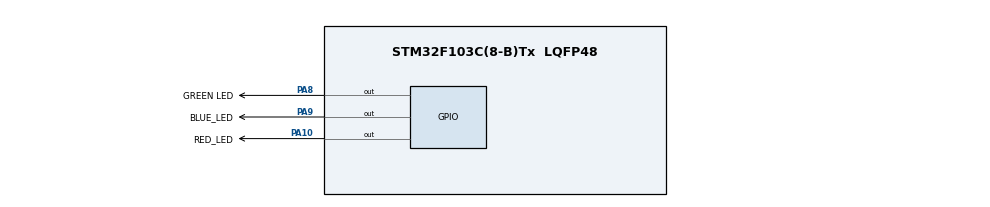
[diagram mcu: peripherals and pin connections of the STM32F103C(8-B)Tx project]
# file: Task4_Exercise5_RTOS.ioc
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FREERTOS.Tasks01=defaultTask,24,128,StartDefaultTask,Default,NULL,Dynamic,NULL,NULL;GreenLedTask,24,128,FlashGreenLedTask,Default,NULL,Dynamic,NULL,NULL;RedLedTask,32,128,FlashRedLedTask,Default,NULL,Dynamic,NULL,NULL
FREERTOS.configUSE_NEWLIB_REENTRANT=1
Mcu.Family=STM32F1
Mcu.Name=STM32F103C(8-B)Tx
Mcu.Package=LQFP48
NVIC.PriorityGroup=NVIC_PRIORITYGROUP_4
NVIC.TIM4_IRQn=true\:15\:0\:false\:false\:true\:false\:false\:true\:true
NVIC.TimeBase=TIM4_IRQn
NVIC.TimeBaseIP=TIM4
PA10.GPIO_Label=RED_LED
PA10.Signal=GPIO_Output
PA13.Mode=Serial_Wire
PA13.Signal=SYS_JTMS-SWDIO
PA14.Mode=Serial_Wire
PA14.Signal=SYS_JTCK-SWCLK
PA8.GPIO_Label=GREEN LED
PA8.Signal=GPIO_Output
PA9.GPIO_Label=BLUE_LED
PA9.Signal=GPIO_Output
ProjectManager.HeapSize=0x200
ProjectManager.StackSize=0x400
ProjectManager.TargetToolchain=STM32CubeIDE
RCC.APB1Freq_Value=8000000
RCC.APB2Freq_Value=8000000
VP_FREERTOS_VS_CMSIS_V2.Mode=CMSIS_V2
VP_SYS_VS_tim4.Mode=TIM4
board=custom

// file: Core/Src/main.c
/* USER CODE BEGIN Header */
/**
  ******************************************************************************
  * @file           : main.c
  * @brief          : Main program body
  ******************************************************************************
  * @attention
  *
  * Copyright (c) 2024 STMicroelectronics.
  * All rights reserved.
  *
  * This software is licensed under terms that can be found in the LICENSE file
  * in the root directory of this software component.
  * If no LICENSE file comes with this software, it is provided AS-IS.
  *
  ******************************************************************************
  */
/* USER CODE END Header */
#include "main.h"
#include "cmsis_os.h"

/* Definitions for defaultTask */
osThreadId_t defaultTaskHandle;
const osThreadAttr_t defaultTask_attributes = {
  .name = "defaultTask",
  .stack_size = 128 * 4,
  .priority = (osPriority_t) osPriorityNormal,
};
/* Definitions for GreenLedTask */
osThreadId_t GreenLedTaskHandle;
const osThreadAttr_t GreenLedTask_attributes = {
  .name = "GreenLedTask",
  .stack_size = 128 * 4,
  .priority = (osPriority_t) osPriorityNormal,
};
/* Definitions for RedLedTask */
osThreadId_t RedLedTaskHandle;
const osThreadAttr_t RedLedTask_attributes = {
  .name = "RedLedTask",
  .stack_size = 128 * 4,
  .priority = (osPriority_t) osPriorityAboveNormal,
};

void SystemClock_Config(void);
static void MX_GPIO_Init(void);
void StartDefaultTask(void *argument);
void FlashGreenLedTask(void *argument);
void FlashRedLedTask(void *argument);

/* USER CODE BEGIN PFP */
uint8_t Start_Flag = 1; // 1 = Up, 0 = Down
void AccessSharedData(void);

/* USER CODE END PFP */

int main(void)
{

  /* MCU Configuration--------------------------------------------------------*/

  /* Reset of all peripherals, Initializes the Flash interface and the Systick. */
  HAL_Init();

  /* Configure the system clock */
  SystemClock_Config();

  /* Initialize all configured peripherals */
  MX_GPIO_Init();

  /* Init scheduler */
  osKernelInitialize();

  /* Create the thread(s) */
  /* creation of defaultTask */
  defaultTaskHandle = osThreadNew(StartDefaultTask, NULL, &defaultTask_attributes);

  /* creation of GreenLedTask */
  GreenLedTaskHandle = osThreadNew(FlashGreenLedTask, NULL, &GreenLedTask_attributes);

  /* creation of RedLedTask */
  RedLedTaskHandle = osThreadNew(FlashRedLedTask, NULL, &RedLedTask_attributes);

  /* Start scheduler */
  osKernelStart();

  /* We should never get here as control is now taken by the scheduler */

  /* Infinite loop */
  while (1)
  {

  }
}

void SystemClock_Config(void)
{
  RCC_OscInitTypeDef RCC_OscInitStruct = {0};
  RCC_ClkInitTypeDef RCC_ClkInitStruct = {0};

  /** Initializes the RCC Oscillators according to the specified parameters
  * in the RCC_OscInitTypeDef structure.
  */
  RCC_OscInitStruct.OscillatorType = RCC_OSCILLATORTYPE_HSI;
  RCC_OscInitStruct.HSIState = RCC_HSI_ON;
  RCC_OscInitStruct.HSICalibrationValue = RCC_HSICALIBRATION_DEFAULT;
  RCC_OscInitStruct.PLL.PLLState = RCC_PLL_NONE;
  if (HAL_RCC_OscConfig(&RCC_OscInitStruct) != HAL_OK)
  {
    Error_Handler();
  }

  /** Initializes the CPU, AHB and APB buses clocks
  */
  RCC_ClkInitStruct.ClockType = RCC_CLOCKTYPE_HCLK|RCC_CLOCKTYPE_SYSCLK
                              |RCC_CLOCKTYPE_PCLK1|RCC_CLOCKTYPE_PCLK2;
  RCC_ClkInitStruct.SYSCLKSource = RCC_SYSCLKSOURCE_HSI;
  RCC_ClkInitStruct.AHBCLKDivider = RCC_SYSCLK_DIV1;
  RCC_ClkInitStruct.APB1CLKDivider = RCC_HCLK_DIV1;
  RCC_ClkInitStruct.APB2CLKDivider = RCC_HCLK_DIV1;

  if (HAL_RCC_ClockConfig(&RCC_ClkInitStruct, FLASH_LATENCY_0) != HAL_OK)
  {
    Error_Handler();
  }
}

static void MX_GPIO_Init(void)
{
  GPIO_InitTypeDef GPIO_InitStruct = {0};

  /* GPIO Ports Clock Enable */
  __HAL_RCC_GPIOA_CLK_ENABLE();

  /*Configure GPIO pin Output Level */
  HAL_GPIO_WritePin(GPIOA, GREEN_LED_Pin|BLUE_LED_Pin|RED_LED_Pin, GPIO_PIN_RESET);

  /*Configure GPIO pins : GREEN_LED_Pin BLUE_LED_Pin RED_LED_Pin */
  GPIO_InitStruct.Pin = GREEN_LED_Pin|BLUE_LED_Pin|RED_LED_Pin;
  GPIO_InitStruct.Mode = GPIO_MODE_OUTPUT_PP;
  GPIO_InitStruct.Pull = GPIO_NOPULL;
  GPIO_InitStruct.Speed = GPIO_SPEED_FREQ_LOW;
  HAL_GPIO_Init(GPIOA, &GPIO_InitStruct);

}

/* USER CODE BEGIN 4 */
void AccessSharedData(void) {
	if (Start_Flag == 1)
	  {
	    Start_Flag = 0;
	  }
	  else
	  {
	    HAL_GPIO_WritePin(BLUE_LED_GPIO_Port, BLUE_LED_Pin, GPIO_PIN_SET);
	  }
	  HAL_Delay(500);
	  Start_Flag = 1;
	  HAL_GPIO_WritePin(BLUE_LED_GPIO_Port, BLUE_LED_Pin, GPIO_PIN_RESET);
}
/* USER CODE END 4 */

void StartDefaultTask(void *argument)
{
  for(;;)
  {
    osDelay(1);
  }
}

void FlashGreenLedTask(void *argument)
{
  /* USER CODE BEGIN FlashGreenLedTask */
  /* Infinite loop */
  for(;;)
  {
	  HAL_GPIO_WritePin(GREEN_LED_GPIO_Port, GREEN_LED_Pin, GPIO_PIN_SET); // Turn on Green LED
	  AccessSharedData();
	  HAL_GPIO_WritePin(GREEN_LED_GPIO_Port, GREEN_LED_Pin, GPIO_PIN_RESET); // Turn off Green LED
	  osDelay(500); // Delay for 0.5 seconds
  }
  /* USER CODE END FlashGreenLedTask */
}

void FlashRedLedTask(void *argument)
{
  /* USER CODE BEGIN FlashRedLedTask */
  /* Infinite loop */
  for(;;)
  {
	HAL_GPIO_WritePin(RED_LED_GPIO_Port, RED_LED_Pin, GPIO_PIN_SET); // Turn on Red LED
	AccessSharedData();
	HAL_GPIO_WritePin(RED_LED_GPIO_Port, RED_LED_Pin, GPIO_PIN_RESET); // Turn off Red LED
	osDelay(100); // Delay for 0.1 seconds
  }
  /* USER CODE END FlashRedLedTask */
}

void HAL_TIM_PeriodElapsedCallback(TIM_HandleTypeDef *htim)
{
  if (htim->Instance == TIM4) {
    HAL_IncTick();
  }
}

void Error_Handler(void)
{
  __disable_irq();
  while (1)
  {
  }
}
